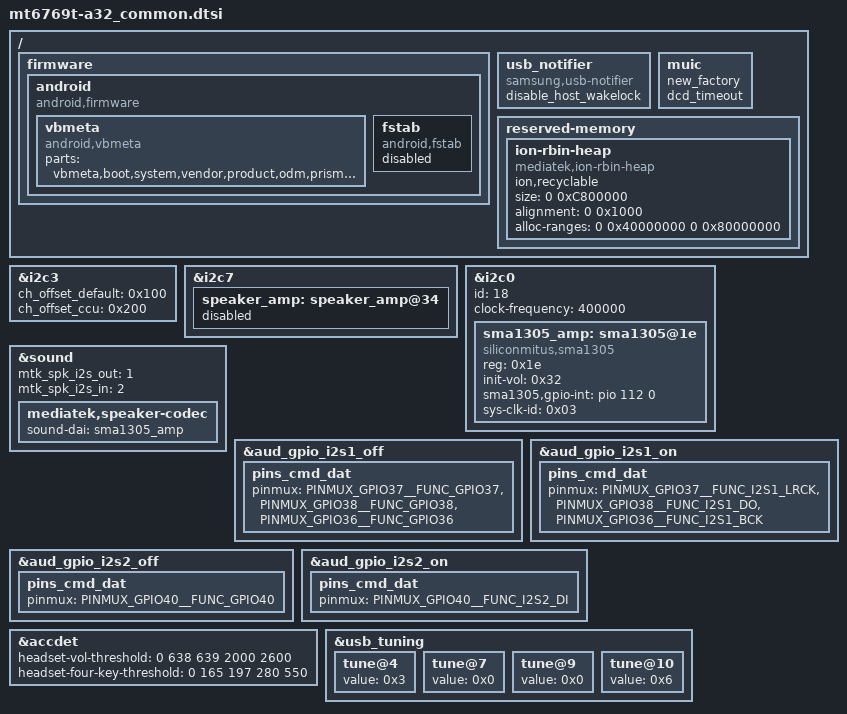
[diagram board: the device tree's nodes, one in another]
/* Generated by Samsung for MTK vendor board
 * If these files should be changed, then please make a sync with MTK
*/


#include "display_lcd_a32_common.dtsi"

/* Add Samsung configuration over here */
/ {
	fragment@model {
		target-path = "/";
		__overlay__ {
			firmware {
				android {
					compatible = "android,firmware";
					vbmeta {
						compatible = "android,vbmeta";
						parts = "vbmeta,boot,system,vendor,product,odm,prism,optics,vbmeta_system,recovery,lk,tee1";
					};
					fstab {
						compatible = "android,fstab";
						status = "disabled";
					};
				};
			};
			usb_notifier {
				compatible = "samsung,usb-notifier";
				disable_host_wakelock;
			};
			muic {
				new_factory;
				dcd_timeout;
			};
			reserved-memory {
				ion-rbin-heap {
					compatible = "mediatek,ion-rbin-heap";
					ion,recyclable;
					size = <0 0xC800000>;
					alignment = <0 0x1000>;
					alloc-ranges = <0 0x40000000 0 0x80000000>;
				};
			};			

		};
	};
};

&i2c3 {
	ch_offset_default = <0x100>;
	ch_offset_ccu = <0x200>;
};

&i2c7 {
	speaker_amp: speaker_amp@34 {
		status = "disabled";
	};
};

&i2c0 {
	status = "okay";
	id = <18>;
	clock-frequency = <400000>;
	#address-cells = <1>;
	#size-cells = <0>;

	sma1305_amp: sma1305@1e {
		#sound-dai-cells = <0>;

		compatible = "siliconmitus,sma1305";
		reg = <0x1e>;
		init-vol = <0x32>;
		sma1305,gpio-int= <&pio 112 0>;
		sys-clk-id = <0x03>;
		status = "okay";
	};
};

&sound {
	mtk_spk_i2s_out = <1>;
	mtk_spk_i2s_in = <2>;
	mediatek,speaker-codec {
		sound-dai = <&sma1305_amp>;
	};
};

/* I2S gpio configuration */
&aud_gpio_i2s1_off {
	pins_cmd_dat {
		pinmux = <PINMUX_GPIO37__FUNC_GPIO37>,
			 <PINMUX_GPIO38__FUNC_GPIO38>,
			 <PINMUX_GPIO36__FUNC_GPIO36>;
	};
};

&aud_gpio_i2s1_on {
	pins_cmd_dat {
		pinmux = <PINMUX_GPIO37__FUNC_I2S1_LRCK>,
			 <PINMUX_GPIO38__FUNC_I2S1_DO>,
			 <PINMUX_GPIO36__FUNC_I2S1_BCK>;
	};
};

&aud_gpio_i2s2_off {
	pins_cmd_dat {
		pinmux = <PINMUX_GPIO40__FUNC_GPIO40>;
	};
};

&aud_gpio_i2s2_on {
	pins_cmd_dat {
		pinmux = <PINMUX_GPIO40__FUNC_I2S2_DI>;
	};
};

&accdet {
	/*min_3pole--max_3pole--min_4pole--max_4pole--vol_bias*/
	headset-vol-threshold = <0 638 639 2000 2600>;
	/*0--MD_MAX--VOICE_MAX--UP_MAX--DW_MAX*/
	headset-four-key-threshold = <0 165 197 280 550>;
};

&usb_tuning {
	/* term_vref_sel */
	tune@4 {
		value = <0x3>;
	};
	/* hstx_srctrl */
	tune@7 {
		value = <0x0>;
	};
	/* sqth */
	tune@9 {
		value = <0x0>;
	};
	/* discth */
	tune@10 {
		value = <0x6>;
	};
};
